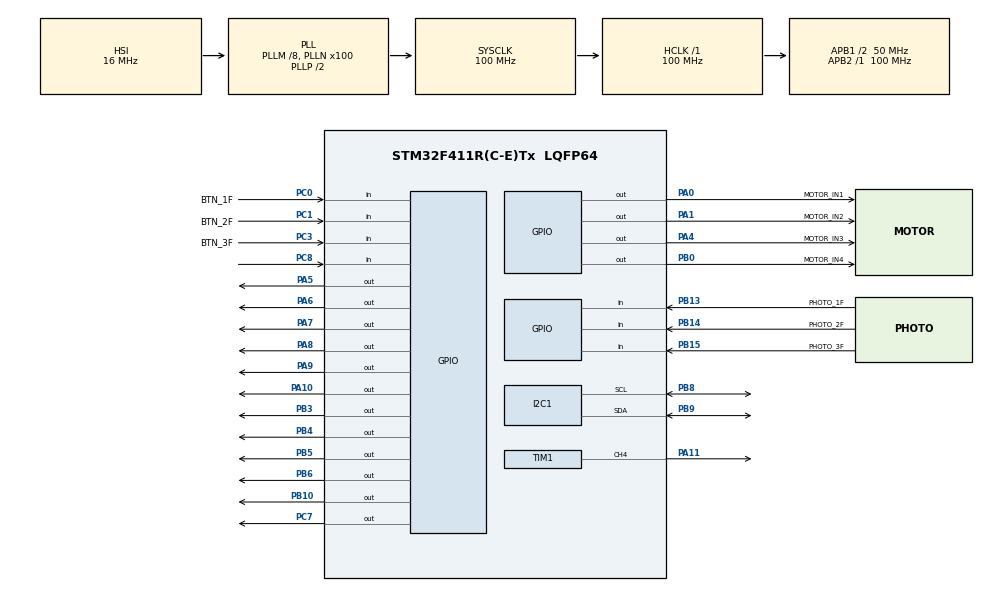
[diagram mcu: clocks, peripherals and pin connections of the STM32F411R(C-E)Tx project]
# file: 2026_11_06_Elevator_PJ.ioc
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Mcu.Family=STM32F4
Mcu.Name=STM32F411R(C-E)Tx
Mcu.Package=LQFP64
NVIC.PriorityGroup=NVIC_PRIORITYGROUP_4
PA0-WKUP.GPIO_Label=MOTOR_IN1
PA0-WKUP.Signal=GPIO_Output
PA1.GPIO_Label=MOTOR_IN2
PA1.Signal=GPIO_Output
PA10.Signal=GPIO_Output
PA11.Signal=S_TIM1_CH4
PA13.Mode=Serial_Wire
PA13.Signal=SYS_JTMS-SWDIO
PA14.Mode=Serial_Wire
PA14.Signal=SYS_JTCK-SWCLK
PA4.GPIO_Label=MOTOR_IN3
PA4.Signal=GPIO_Output
PA5.Signal=GPIO_Output
PA6.Signal=GPIO_Output
PA7.Signal=GPIO_Output
PA8.Signal=GPIO_Output
PA9.Signal=GPIO_Output
PB0.GPIO_Label=MOTOR_IN4
PB0.Signal=GPIO_Output
PB10.Signal=GPIO_Output
PB13.GPIO_Label=PHOTO_1F
PB13.Signal=GPIO_Input
PB14.GPIO_Label=PHOTO_2F
PB14.Signal=GPIO_Input
PB15.GPIO_Label=PHOTO_3F
PB15.Signal=GPIO_Input
PB3.Signal=GPIO_Output
PB4.Signal=GPIO_Output
PB5.Signal=GPIO_Output
PB6.Signal=GPIO_Output
PB8.Mode=I2C
PB8.Signal=I2C1_SCL
PB9.Mode=I2C
PB9.Signal=I2C1_SDA
PC0.GPIO_Label=BTN_1F
PC0.Signal=GPIO_Input
PC1.GPIO_Label=BTN_2F
PC1.Signal=GPIO_Input
PC3.GPIO_Label=BTN_3F
PC3.Signal=GPIO_Input
PC7.Signal=GPIO_Output
PC8.Signal=GPIO_Input
PH0\ -\ OSC_IN.Mode=HSE-External-Oscillator
PH0\ -\ OSC_IN.Signal=RCC_OSC_IN
PH1\ -\ OSC_OUT.Mode=HSE-External-Oscillator
PH1\ -\ OSC_OUT.Signal=RCC_OSC_OUT
ProjectManager.HeapSize=0x200
ProjectManager.StackSize=0x400
ProjectManager.TargetToolchain=STM32CubeIDE
RCC.48MHZClocksFreq_Value=50000000
RCC.AHBFreq_Value=100000000
RCC.APB1CLKDivider=RCC_HCLK_DIV2
RCC.APB1Freq_Value=50000000
RCC.APB1TimFreq_Value=100000000
RCC.APB2Freq_Value=100000000
RCC.APB2TimFreq_Value=100000000
RCC.CortexFreq_Value=100000000
RCC.HCLKFreq_Value=100000000
RCC.HSE_VALUE=8000000
RCC.HSI_VALUE=16000000
RCC.LSE_VALUE=32768
RCC.PLLM=8
RCC.PLLN=100
RCC.SYSCLKFreq_VALUE=100000000
RCC.SYSCLKSource=RCC_SYSCLKSOURCE_PLLCLK
RCC.VCOOutputFreq_Value=200000000
SH.S_TIM1_CH4.0=TIM1_CH4,PWM Generation4 CH4
TIM1.Channel-PWM\ Generation4\ CH4=TIM_CHANNEL_4
board=custom

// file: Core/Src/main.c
/* USER CODE BEGIN Header */
/**
  ******************************************************************************
  * @file           : main.c
  * @brief          : Main program body
  ******************************************************************************
  * @attention
  *
  * Copyright (c) 2026 STMicroelectronics.
  * All rights reserved.
  *
  * This software is licensed under terms that can be found in the LICENSE file
  * in the root directory of this software component.
  * If no LICENSE file comes with this software, it is provided AS-IS.
  *
  ******************************************************************************
  */
/* USER CODE END Header */
#include "main.h"

/* USER CODE BEGIN Includes */
#include "elevator.h"
#include "stepmotor.h"

/* USER CODE END Includes */

I2C_HandleTypeDef hi2c1;

TIM_HandleTypeDef htim1;

void SystemClock_Config(void);
static void MX_GPIO_Init(void);
static void MX_I2C1_Init(void);
static void MX_TIM1_Init(void);

int main(void)
{

  /* MCU Configuration--------------------------------------------------------*/

  /* Reset of all peripherals, Initializes the Flash interface and the Systick. */
  HAL_Init();

  /* Configure the system clock */
  SystemClock_Config();

  /* Initialize all configured peripherals */
  MX_GPIO_Init();
  MX_I2C1_Init();
  MX_TIM1_Init();
  /* USER CODE BEGIN 2 */
  Elevator_Init();
  /* Input commissioning: no automatic motion after boot/reset. */

  /* USER CODE END 2 */

  /* Infinite loop */
  while (1)
  {

    /* USER CODE BEGIN 3 */
    Elevator_Run(HAL_GetTick());
  }
  /* USER CODE END 3 */
}

void SystemClock_Config(void)
{
  RCC_OscInitTypeDef RCC_OscInitStruct = {0};
  RCC_ClkInitTypeDef RCC_ClkInitStruct = {0};

  /** Configure the main internal regulator output voltage
  */
  __HAL_RCC_PWR_CLK_ENABLE();
  __HAL_PWR_VOLTAGESCALING_CONFIG(PWR_REGULATOR_VOLTAGE_SCALE1);

  /** Initializes the RCC Oscillators according to the specified parameters
  * in the RCC_OscInitTypeDef structure.
  */
  RCC_OscInitStruct.OscillatorType = RCC_OSCILLATORTYPE_HSI;
  RCC_OscInitStruct.HSIState = RCC_HSI_ON;
  RCC_OscInitStruct.HSICalibrationValue = RCC_HSICALIBRATION_DEFAULT;
  RCC_OscInitStruct.PLL.PLLState = RCC_PLL_ON;
  RCC_OscInitStruct.PLL.PLLSource = RCC_PLLSOURCE_HSI;
  RCC_OscInitStruct.PLL.PLLM = 8;
  RCC_OscInitStruct.PLL.PLLN = 100;
  RCC_OscInitStruct.PLL.PLLP = RCC_PLLP_DIV2;
  RCC_OscInitStruct.PLL.PLLQ = 4;
  if (HAL_RCC_OscConfig(&RCC_OscInitStruct) != HAL_OK)
  {
    Error_Handler();
  }

  /** Initializes the CPU, AHB and APB buses clocks
  */
  RCC_ClkInitStruct.ClockType = RCC_CLOCKTYPE_HCLK|RCC_CLOCKTYPE_SYSCLK
                              |RCC_CLOCKTYPE_PCLK1|RCC_CLOCKTYPE_PCLK2;
  RCC_ClkInitStruct.SYSCLKSource = RCC_SYSCLKSOURCE_PLLCLK;
  RCC_ClkInitStruct.AHBCLKDivider = RCC_SYSCLK_DIV1;
  RCC_ClkInitStruct.APB1CLKDivider = RCC_HCLK_DIV2;
  RCC_ClkInitStruct.APB2CLKDivider = RCC_HCLK_DIV1;

  if (HAL_RCC_ClockConfig(&RCC_ClkInitStruct, FLASH_LATENCY_3) != HAL_OK)
  {
    Error_Handler();
  }
}

static void MX_I2C1_Init(void)
{

  hi2c1.Instance = I2C1;
  hi2c1.Init.ClockSpeed = 100000;
  hi2c1.Init.DutyCycle = I2C_DUTYCYCLE_2;
  hi2c1.Init.OwnAddress1 = 0;
  hi2c1.Init.AddressingMode = I2C_ADDRESSINGMODE_7BIT;
  hi2c1.Init.DualAddressMode = I2C_DUALADDRESS_DISABLE;
  hi2c1.Init.OwnAddress2 = 0;
  hi2c1.Init.GeneralCallMode = I2C_GENERALCALL_DISABLE;
  hi2c1.Init.NoStretchMode = I2C_NOSTRETCH_DISABLE;
  if (HAL_I2C_Init(&hi2c1) != HAL_OK)
  {
    Error_Handler();
  }

}

static void MX_TIM1_Init(void)
{

  TIM_MasterConfigTypeDef sMasterConfig = {0};
  TIM_OC_InitTypeDef sConfigOC = {0};
  TIM_BreakDeadTimeConfigTypeDef sBreakDeadTimeConfig = {0};

  htim1.Instance = TIM1;
  htim1.Init.Prescaler = 0;
  htim1.Init.CounterMode = TIM_COUNTERMODE_UP;
  htim1.Init.Period = 65535;
  htim1.Init.ClockDivision = TIM_CLOCKDIVISION_DIV1;
  htim1.Init.RepetitionCounter = 0;
  htim1.Init.AutoReloadPreload = TIM_AUTORELOAD_PRELOAD_DISABLE;
  if (HAL_TIM_PWM_Init(&htim1) != HAL_OK)
  {
    Error_Handler();
  }
  sMasterConfig.MasterOutputTrigger = TIM_TRGO_RESET;
  sMasterConfig.MasterSlaveMode = TIM_MASTERSLAVEMODE_DISABLE;
  if (HAL_TIMEx_MasterConfigSynchronization(&htim1, &sMasterConfig) != HAL_OK)
  {
    Error_Handler();
  }
  sConfigOC.OCMode = TIM_OCMODE_PWM1;
  sConfigOC.Pulse = 0;
  sConfigOC.OCPolarity = TIM_OCPOLARITY_HIGH;
  sConfigOC.OCFastMode = TIM_OCFAST_DISABLE;
  sConfigOC.OCIdleState = TIM_OCIDLESTATE_RESET;
  sConfigOC.OCNIdleState = TIM_OCNIDLESTATE_RESET;
  if (HAL_TIM_PWM_ConfigChannel(&htim1, &sConfigOC, TIM_CHANNEL_4) != HAL_OK)
  {
    Error_Handler();
  }
  sBreakDeadTimeConfig.OffStateRunMode = TIM_OSSR_DISABLE;
  sBreakDeadTimeConfig.OffStateIDLEMode = TIM_OSSI_DISABLE;
  sBreakDeadTimeConfig.LockLevel = TIM_LOCKLEVEL_OFF;
  sBreakDeadTimeConfig.DeadTime = 0;
  sBreakDeadTimeConfig.BreakState = TIM_BREAK_DISABLE;
  sBreakDeadTimeConfig.BreakPolarity = TIM_BREAKPOLARITY_HIGH;
  sBreakDeadTimeConfig.AutomaticOutput = TIM_AUTOMATICOUTPUT_DISABLE;
  if (HAL_TIMEx_ConfigBreakDeadTime(&htim1, &sBreakDeadTimeConfig) != HAL_OK)
  {
    Error_Handler();
  }
  HAL_TIM_MspPostInit(&htim1);

}

static void MX_GPIO_Init(void)
{
  GPIO_InitTypeDef GPIO_InitStruct = {0};

  /* GPIO Ports Clock Enable */
  __HAL_RCC_GPIOH_CLK_ENABLE();
  __HAL_RCC_GPIOC_CLK_ENABLE();
  __HAL_RCC_GPIOA_CLK_ENABLE();
  __HAL_RCC_GPIOB_CLK_ENABLE();

  /*Configure GPIO pin Output Level */
  HAL_GPIO_WritePin(GPIOA, MOTOR_IN1_Pin|MOTOR_IN2_Pin|MOTOR_IN3_Pin|GPIO_PIN_5
                          |GPIO_PIN_6|GPIO_PIN_7|GPIO_PIN_8|GPIO_PIN_9
                          |GPIO_PIN_10, GPIO_PIN_RESET);

  /*Configure GPIO pin Output Level */
  HAL_GPIO_WritePin(GPIOB, MOTOR_IN4_Pin|GPIO_PIN_10|GPIO_PIN_3|GPIO_PIN_4
                          |GPIO_PIN_5|GPIO_PIN_6, GPIO_PIN_RESET);

  /*Configure GPIO pin Output Level */
  HAL_GPIO_WritePin(GPIOC, GPIO_PIN_7, GPIO_PIN_RESET);

  /*Configure GPIO pins : BTN_1F_Pin BTN_2F_Pin BTN_3F_Pin PC8 */
  GPIO_InitStruct.Pin = BTN_1F_Pin|BTN_2F_Pin|BTN_3F_Pin|GPIO_PIN_8;
  GPIO_InitStruct.Mode = GPIO_MODE_INPUT;
  GPIO_InitStruct.Pull = GPIO_NOPULL;
  HAL_GPIO_Init(GPIOC, &GPIO_InitStruct);

  /*Configure GPIO pins : MOTOR_IN1_Pin MOTOR_IN2_Pin MOTOR_IN3_Pin PA5
                           PA6 PA7 PA8 PA9
                           PA10 */
  GPIO_InitStruct.Pin = MOTOR_IN1_Pin|MOTOR_IN2_Pin|MOTOR_IN3_Pin|GPIO_PIN_5
                          |GPIO_PIN_6|GPIO_PIN_7|GPIO_PIN_8|GPIO_PIN_9
                          |GPIO_PIN_10;
  GPIO_InitStruct.Mode = GPIO_MODE_OUTPUT_PP;
  GPIO_InitStruct.Pull = GPIO_NOPULL;
  GPIO_InitStruct.Speed = GPIO_SPEED_FREQ_LOW;
  HAL_GPIO_Init(GPIOA, &GPIO_InitStruct);

  /*Configure GPIO pins : MOTOR_IN4_Pin PB10 PB3 PB4
                           PB5 PB6 */
  GPIO_InitStruct.Pin = MOTOR_IN4_Pin|GPIO_PIN_10|GPIO_PIN_3|GPIO_PIN_4
                          |GPIO_PIN_5|GPIO_PIN_6;
  GPIO_InitStruct.Mode = GPIO_MODE_OUTPUT_PP;
  GPIO_InitStruct.Pull = GPIO_NOPULL;
  GPIO_InitStruct.Speed = GPIO_SPEED_FREQ_LOW;
  HAL_GPIO_Init(GPIOB, &GPIO_InitStruct);

  /*Configure GPIO pins : PHOTO_1F_Pin PHOTO_2F_Pin PHOTO_3F_Pin */
  GPIO_InitStruct.Pin = PHOTO_1F_Pin|PHOTO_2F_Pin|PHOTO_3F_Pin;
  GPIO_InitStruct.Mode = GPIO_MODE_INPUT;
  GPIO_InitStruct.Pull = GPIO_NOPULL;
  HAL_GPIO_Init(GPIOB, &GPIO_InitStruct);

  /*Configure GPIO pin : PC7 */
  GPIO_InitStruct.Pin = GPIO_PIN_7;
  GPIO_InitStruct.Mode = GPIO_MODE_OUTPUT_PP;
  GPIO_InitStruct.Pull = GPIO_NOPULL;
  GPIO_InitStruct.Speed = GPIO_SPEED_FREQ_LOW;
  HAL_GPIO_Init(GPIOC, &GPIO_InitStruct);

}

void Error_Handler(void)
{
  /* USER CODE BEGIN Error_Handler_Debug */
  StepMotor_Stop();
  /* User can add his own implementation to report the HAL error return state */
  __disable_irq();
  while (1)
  {
  }
  /* USER CODE END Error_Handler_Debug */
}
